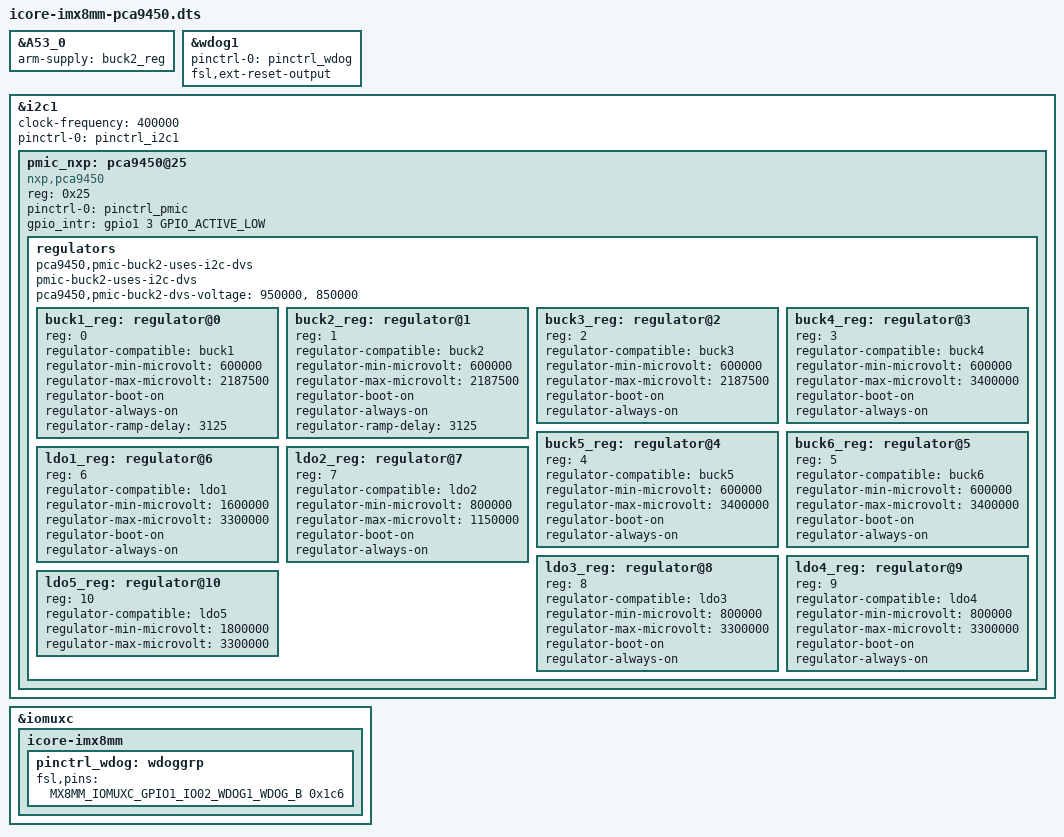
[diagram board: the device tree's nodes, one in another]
// SPDX-License-Identifier: (GPL-2.0+ OR MIT)
/*
 * Copyright 2019 NXP
 */

/dts-v1/;

#include "icore-imx8mm.dts"

/{
	/delete-node/ gpio-restart;
};

&A53_0 {
	arm-supply = <&buck2_reg>;
};

&wdog1 {
	pinctrl-names = "default";
	pinctrl-0 = <&pinctrl_wdog>;
	fsl,ext-reset-output;
	status = "okay";
};


&i2c1 {
	clock-frequency = <400000>;
	pinctrl-names = "default";
	pinctrl-0 = <&pinctrl_i2c1>;
	status = "okay";

	/delete-node/ pf8100;

	pmic_nxp: pca9450@25 {
		reg = <0x25>;
		compatible = "nxp,pca9450";
		/* PMIC PCA9450 PMIC_nINT GPIO1_IO3 */
		pinctrl-0 = <&pinctrl_pmic>;
		gpio_intr = <&gpio1 3 GPIO_ACTIVE_LOW>;

		regulators {
			#address-cells = <1>;
			#size-cells = <0>;

			pca9450,pmic-buck2-uses-i2c-dvs;
			pmic-buck2-uses-i2c-dvs;
			/* Run/Standby voltage */
			pca9450,pmic-buck2-dvs-voltage = <950000>, <850000>;

			buck1_reg: regulator@0 {
				reg = <0>;
				regulator-compatible = "buck1";
				regulator-min-microvolt = <600000>;
				regulator-max-microvolt = <2187500>;
				regulator-boot-on;
				regulator-always-on;
				regulator-ramp-delay = <3125>;
			};

			buck2_reg: regulator@1 {
				reg = <1>;
				regulator-compatible = "buck2";
				regulator-min-microvolt = <600000>;
				regulator-max-microvolt = <2187500>;
				regulator-boot-on;
				regulator-always-on;
				regulator-ramp-delay = <3125>;
			};

			buck3_reg: regulator@2 {
				reg = <2>;
				regulator-compatible = "buck3";
				regulator-min-microvolt = <600000>;
				regulator-max-microvolt = <2187500>;
				regulator-boot-on;
				regulator-always-on;
			};

			buck4_reg: regulator@3 {
				reg = <3>;
				regulator-compatible = "buck4";
				regulator-min-microvolt = <600000>;
				regulator-max-microvolt = <3400000>;
				regulator-boot-on;
				regulator-always-on;
			};

			buck5_reg: regulator@4 {
				reg = <4>;
				regulator-compatible = "buck5";
				regulator-min-microvolt = <600000>;
				regulator-max-microvolt = <3400000>;
				regulator-boot-on;
				regulator-always-on;
			};

			buck6_reg: regulator@5 {
				reg = <5>;
				regulator-compatible = "buck6";
				regulator-min-microvolt = <600000>;
				regulator-max-microvolt = <3400000>;
				regulator-boot-on;
				regulator-always-on;
			};

			ldo1_reg: regulator@6 {
				reg = <6>;
				regulator-compatible = "ldo1";
				regulator-min-microvolt = <1600000>;
				regulator-max-microvolt = <3300000>;
				regulator-boot-on;
				regulator-always-on;
			};

			ldo2_reg: regulator@7 {
				reg = <7>;
				regulator-compatible = "ldo2";
				regulator-min-microvolt = <800000>;
				regulator-max-microvolt = <1150000>;
				regulator-boot-on;
				regulator-always-on;
			};

			ldo3_reg: regulator@8 {
				reg = <8>;
				regulator-compatible = "ldo3";
				regulator-min-microvolt = <800000>;
				regulator-max-microvolt = <3300000>;
				regulator-boot-on;
				regulator-always-on;
			};

			ldo4_reg: regulator@9 {
				reg = <9>;
				regulator-compatible = "ldo4";
				regulator-min-microvolt = <800000>;
				regulator-max-microvolt = <3300000>;
				regulator-boot-on;
				regulator-always-on;
			};

			ldo5_reg: regulator@10 {
				reg = <10>;
				regulator-compatible = "ldo5";
				regulator-min-microvolt = <1800000>;
				regulator-max-microvolt = <3300000>;
			};
		};
	};
};


&iomuxc {
		/delete-property/ pinctrl-0;
		/delete-property/ pinctrl-names;

		icore-imx8mm {

		/delete-node/ pinctrl_hog;

		pinctrl_wdog: wdoggrp {
			fsl,pins = <
				MX8MM_IOMUXC_GPIO1_IO02_WDOG1_WDOG_B	0x1c6
		>;
	};
	};
};
